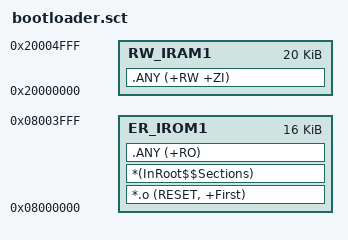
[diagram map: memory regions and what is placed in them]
; LiteBootLoader 散布加载文件 —— BL 区 16 KiB + SRAM 20 KiB（partition.md §1）
LR_IROM1 0x08000000 0x00004000  {
  ER_IROM1 0x08000000 0x00004000  {
    *.o (RESET, +First)
    *(InRoot$$Sections)
    .ANY (+RO)
  }
  RW_IRAM1 0x20000000 0x00005000  {
    .ANY (+RW +ZI)
  }
}
